AUTOSAR XML (schema 4-0-3)
package /ComponentTypes
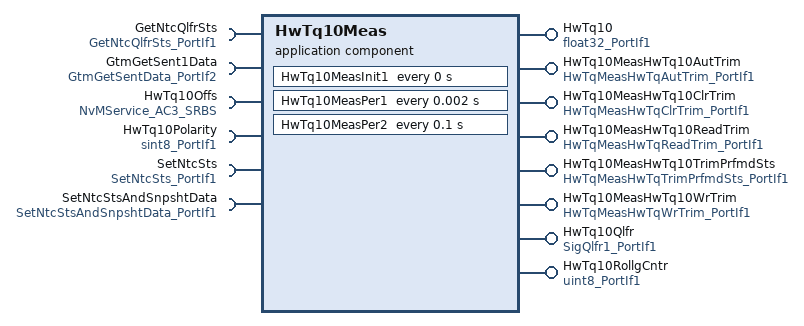
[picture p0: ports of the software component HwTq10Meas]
  application sw component type HwTq10Meas
    8 x provide port:
      HwTq10: nonqueued-sender-com-spec{data-element=Val, init-value=0}, provided-interface=float32_PortIf1
      HwTq10MeasHwTq10AutTrim: server-com-spec{operation=Oper, queue-length=1}, provided-interface=HwTqMeasHwTqAutTrim_PortIf1
      HwTq10MeasHwTq10ClrTrim: server-com-spec{operation=Oper, queue-length=1}, provided-interface=HwTqMeasHwTqClrTrim_PortIf1
      HwTq10MeasHwTq10ReadTrim: server-com-spec{operation=Oper, queue-length=1}, provided-interface=HwTqMeasHwTqReadTrim_PortIf1
      HwTq10MeasHwTq10TrimPrfmdSts: server-com-spec{operation=Oper, queue-length=1}, provided-interface=HwTqMeasHwTqTrimPrfmdSts_PortIf1
      HwTq10MeasHwTq10WrTrim: server-com-spec{operation=Oper, queue-length=1}, provided-interface=HwTqMeasHwTqWrTrim_PortIf1
      HwTq10Qlfr: nonqueued-sender-com-spec{data-element=Val, init-value=0}, provided-interface=SigQlfr1_PortIf1
      HwTq10RollgCntr: nonqueued-sender-com-spec{data-element=Val, init-value=0}, provided-interface=uint8_PortIf1
    6 x require port:
      GetNtcQlfrSts: client-com-spec=Oper, required-interface=GetNtcQlfrSts_PortIf1
      GtmGetSent1Data: client-com-spec=Oper, required-interface=GtmGetSentData_PortIf2
      HwTq10Offs: required-com-specs=[EraseBlock, GetErrorStatus, InvalidateNvBlock, ReadBlock, SetRamBlockStatus, WriteBlock], required-interface=NvMService_AC3_SRBS
      HwTq10Polarity: nonqueued-receiver-com-spec{data-element=Val, filter=data-filter-type=ALWAYS, init-value=1}, required-interface=sint8_PortIf1
      SetNtcSts: client-com-spec=Oper, required-interface=SetNtcSts_PortIf1
      SetNtcStsAndSnpshtData: client-com-spec=Oper, required-interface=SetNtcStsAndSnpshtData_PortIf1
    behavior HwTq10Meas_InternalBehavior
      ar-typed-per-instance-memorys:
        10 x data, all with sw-calibration-access=READ-ONLY:
          HwTq10DataPlsHiLim: type=uint32
          HwTq10DataPlsLoLim: type=uint32
          HwTq10Offs: type=HwTqOffsRec1
          HwTq10PrevHwTq: type=float32
          HwTq10RawDataBuf: type=Ary1D_u16_5
          HwTq10RollgCntrPrev: type=uint8
          HwTq10SyncPlsHiLim: type=uint32
          HwTq10SyncPlsLoLim: type=uint32
          HwTq10TiStamp: type=uint32
          HwTq10TiStampPrev: type=uint32
      5 x operation invoked event:
        OIT_HwTq10MeasHwTq10AutTrim_Oper_HwTq10MeasHwTq10AutTrim_Oper: start-on-event=HwTq10MeasHwTq10AutTrim_Oper, operation=HwTq10MeasHwTq10AutTrim.Oper
        OIT_HwTq10MeasHwTq10ClrTrim_Oper_HwTq10MeasHwTq10ClrTrim_Oper: start-on-event=HwTq10MeasHwTq10ClrTrim_Oper, operation=HwTq10MeasHwTq10ClrTrim.Oper
        OIT_HwTq10MeasHwTq10ReadTrim_Oper_HwTq10MeasHwTq10ReadTrim_Oper: start-on-event=HwTq10MeasHwTq10ReadTrim_Oper, operation=HwTq10MeasHwTq10ReadTrim.Oper
        OIT_HwTq10MeasHwTq10TrimPrfmdSts_Oper_HwTq10MeasHwTq10TrimPrfmdSts_Oper: start-on-event=HwTq10MeasHwTq10TrimPrfmdSts_Oper, operation=HwTq10MeasHwTq10TrimPrfmdSts.Oper
        OIT_HwTq10MeasHwTq10WrTrim_Oper_HwTq10MeasHwTq10WrTrim_Oper: start-on-event=HwTq10MeasHwTq10WrTrim_Oper, operation=HwTq10MeasHwTq10WrTrim.Oper
      timing event HwTq10Meas_InitEvent: start-on-event=HwTq10MeasInit1, period=0
      timing event TMT_HwTq10MeasPer1: start-on-event=HwTq10MeasPer1, period=0.002
      timing event TMT_HwTq10MeasPer2: start-on-event=HwTq10MeasPer2, period=0.1
      8 x runnable:
        HwTq10MeasHwTq10AutTrim_Oper
          sync call SC_HwTq10Offs_SetRamBlockStatus: operation=HwTq10Offs.SetRamBlockStatus, timeout=0
        HwTq10MeasHwTq10ClrTrim_Oper
          sync call SC_HwTq10Offs_SetRamBlockStatus: operation=HwTq10Offs.SetRamBlockStatus, timeout=0
        HwTq10MeasHwTq10ReadTrim_Oper
        HwTq10MeasHwTq10TrimPrfmdSts_Oper
        HwTq10MeasHwTq10WrTrim_Oper
          sync call SC_HwTq10Offs_SetRamBlockStatus: operation=HwTq10Offs.SetRamBlockStatus, timeout=0
        HwTq10MeasInit1
          sync call SC_HwTq10Offs_GetErrorStatus: operation=HwTq10Offs.GetErrorStatus, timeout=0
        HwTq10MeasPer1
          data-receive-point-by-arguments:
            access REC_HwTq10Polarity_Val: accessed-variable=HwTq10Polarity.Val
          data-send-points:
            access SEND_HwTq10_Val: accessed-variable=HwTq10.Val
            access SEND_HwTq10Qlfr_Val: accessed-variable=HwTq10Qlfr.Val
            access SEND_HwTq10RollgCntr_Val: accessed-variable=HwTq10RollgCntr.Val
          4 x sync call, all with timeout=0:
            SC_GetNtcQlfrSts_Oper: operation=GetNtcQlfrSts.Oper
            SC_GtmGetSent1Data_Oper: operation=GtmGetSent1Data.Oper
            SC_SetNtcSts_Oper: operation=SetNtcSts.Oper
            SC_SetNtcStsAndSnpshtData_Oper: operation=SetNtcStsAndSnpshtData.Oper
        HwTq10MeasPer2
          sync call SC_SetNtcSts_Oper: operation=SetNtcSts.Oper, timeout=0
      swc service dependency NvmHwTq10Offs: assigned-datas=role-based-data-assignment={role=ramBlock, used-data-element=HwTq10Offs}, assigned-ports=role-based-port-assignment={port-prototype=HwTq10Offs, role=NvMService_AC3_SRBS}
        service-needs:
          nv block needs NvmHwTq10Offs: n-data-sets=0, reliability=ERROR-DETECTION, resistant-to-changed-sw=true, restore-at-start=true, store-at-shutdown=true, writing-priority=LOW
  swc implementation HwTq10Meas_Implementation: behavior=HwTq10Meas_InternalBehavior
    code-descriptors:
      code Default: artifact-descriptors=autosar-engineering-object={short-label=Default, category=SWSRC}
